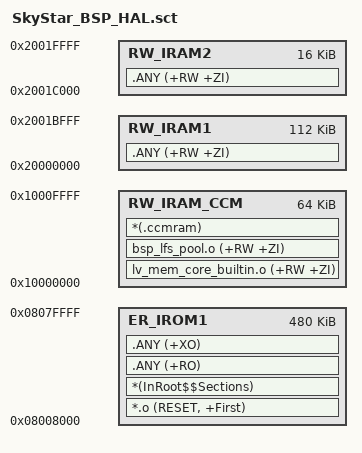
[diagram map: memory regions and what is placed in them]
; *************************************************************
; *** Scatter-Loading Description File generated by uVision ***
; *************************************************************

LR_IROM1 0x08008000 0x00078000  {    ; 480KB App 区（OTA-IAP：前 32KB 让位 Bootloader）
  ER_IROM1 0x08008000 0x00078000  {  ; 运行于 Flash 的代码段与只读数据
   *.o (RESET, +First)
   *(InRoot$$Sections)
   .ANY (+RO)
   .ANY (+XO)
  }
  RW_IRAM1 0x20000000 0x0001C000  {  ; 112KB 物理 SRAM1
   .ANY (+RW +ZI)
  }
  RW_IRAM2 0x2001C000 0x00004000  {  ; 16KB 物理 SRAM2
   .ANY (+RW +ZI)
  }
  RW_IRAM_CCM 0x10000000 0x00010000  { ; 64KB CCM RAM 独立运行域
   lv_mem_core_builtin.o (+RW +ZI)    ; 强制将 LVGL 静态堆移入 CCM RAM
   bsp_lfs_pool.o (+RW +ZI)           ; LittleFS 专用池：flash 读写走轮询 SPI 不经 DMA，可安全占用 CCM
   *(.ccmram)                          ; 将代码中所有修饰为 .ccmram 属性的变量移入此区
  }
}

